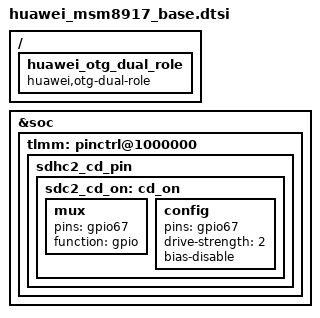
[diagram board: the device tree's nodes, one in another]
/*=============================================================================
                           Huawei Base Dtsi File
  GENERAL DESCRIPTION
    This file is for include the Communal node

  Copyright 2010-2014 by HUAWEI Technologies, Inc.  All Rights Reserved.
=============================================================================*/
#include "msm8917.dtsi"
#include "msm8917-pmi8937-qrd-sku5.dtsi"

/ {
	huawei_otg_dual_role:huawei_otg_dual_role{
		compatible = "huawei,otg-dual-role";
		status = "okay";
	};
};

&soc {
	tlmm: pinctrl@1000000 {
		sdhc2_cd_pin {
			sdc2_cd_on: cd_on {
				mux {
					pins = "gpio67";
					function = "gpio";
				};

				config {
					pins = "gpio67";
					drive-strength = <2>;
					bias-disable;
				};
		   };
		};
	};
};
